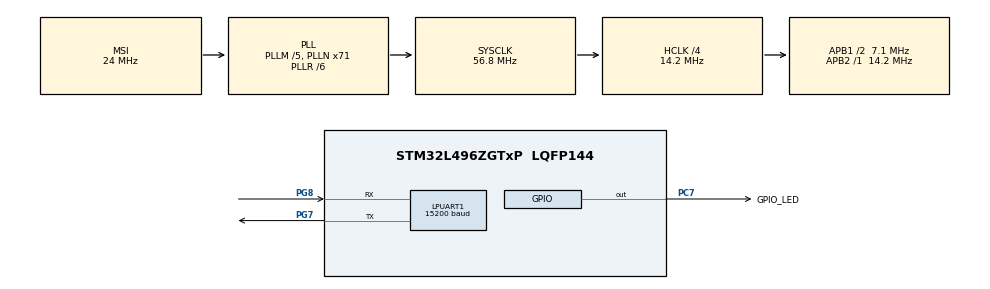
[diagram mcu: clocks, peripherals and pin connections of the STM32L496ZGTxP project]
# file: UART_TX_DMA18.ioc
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Dma.LPUART_TX.0.Direction=DMA_MEMORY_TO_PERIPH
Dma.LPUART_TX.0.Instance=DMA2_Channel6
Dma.LPUART_TX.0.MemDataAlignment=DMA_MDATAALIGN_BYTE
Dma.LPUART_TX.0.MemInc=DMA_MINC_ENABLE
Dma.LPUART_TX.0.Mode=DMA_CIRCULAR
Dma.LPUART_TX.0.PeriphDataAlignment=DMA_PDATAALIGN_BYTE
Dma.LPUART_TX.0.PeriphInc=DMA_PINC_DISABLE
Dma.LPUART_TX.0.Priority=DMA_PRIORITY_LOW
Dma.Request0=LPUART_TX
LPUART1.BaudRate=15200
LPUART1.WordLength=UART_WORDLENGTH_8B
Mcu.Family=STM32L4
Mcu.Name=STM32L496ZGTxP
Mcu.Package=LQFP144
NVIC.DMA2_Channel6_IRQn=true\:0\:0\:false\:false\:true\:false\:true\:true
NVIC.PriorityGroup=NVIC_PRIORITYGROUP_4
PA13\ (JTMS/SWDIO).Signal=SYS_JTMS-SWDIO
PC7.GPIO_Label=GPIO_LED
PC7.Signal=GPIO_Output
PG7.Mode=Asynchronous
PG7.Signal=LPUART1_TX
PG8.Mode=Asynchronous
PG8.Signal=LPUART1_RX
ProjectManager.HeapSize=0x200
ProjectManager.StackSize=0x400
ProjectManager.TargetToolchain=STM32CubeIDE
RCC.48MHZClocksFreq_Value=24000000
RCC.ADCFreq_Value=48000000
RCC.AHBCLKDivider=RCC_SYSCLK_DIV4
RCC.AHBFreq_Value=14200000
RCC.APB1CLKDivider=RCC_HCLK_DIV2
RCC.APB1Freq_Value=7100000
RCC.APB1TimFreq_Value=14200000
RCC.APB2Freq_Value=14200000
RCC.APB2TimFreq_Value=14200000
RCC.CortexFreq_Value=14200000
RCC.HCLKFreq_Value=14200000
RCC.HSE_VALUE=8000000
RCC.HSI48_VALUE=48000000
RCC.HSI_VALUE=16000000
RCC.LSE_VALUE=32768
RCC.MSIClockRange=RCC_MSIRANGE_9
RCC.MSI_VALUE=24000000
RCC.PLLM=5
RCC.PLLMUL=RCC_PLL_MUL9
RCC.PLLN=71
RCC.PLLR=RCC_PLLR_DIV6
RCC.PLLSAI1N=20
RCC.PRESCALERUSB=RCC_USBCLKSOURCE_PLL_DIV1_5
RCC.SYSCLKFreq_VALUE=56800000
RCC.SYSCLKSource=RCC_SYSCLKSOURCE_PLLCLK
RCC.SYSCLKSourceVirtual=RCC_SYSCLKSOURCE_PLLCLK
RCC.USBFreq_Value=48000000
RCC.VCOOutputFreq_Value=340800000
board=NUCLEO-L496ZG-P

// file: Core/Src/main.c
/* USER CODE BEGIN Header */
/**
  ******************************************************************************
  * @file           : main.c
  * @brief          : Main program body
  ******************************************************************************
  * @attention
  *
  * Copyright (c) 2023 STMicroelectronics.
  * All rights reserved.
  *
  * This software is licensed under terms that can be found in the LICENSE file
  * in the root directory of this software component.
  * If no LICENSE file comes with this software, it is provided AS-IS.
  *
  ******************************************************************************
  */
/* USER CODE END Header */
#include "main.h"

UART_HandleTypeDef hlpuart1;
DMA_HandleTypeDef hdma_lpuart_tx;

void SystemClock_Config(void);
static void MX_GPIO_Init(void);
static void MX_DMA_Init(void);
static void MX_LPUART1_UART_Init(void);

/* USER CODE BEGIN 0 */
uint8_t data[20];
uint8_t count =0;

void HAL_UART_TxHalfCpltCallback(UART_HandleTypeDef *huart)
{
  for (int i=0; i<10; i++)
    {
	data[i] = 1;
    }
}

void HAL_UART_TxCpltCallback(UART_HandleTypeDef *huart)
{
    for (int i=0; i<10; i++)
    {
	data[i] = 2;
    }
}

/* USER CODE END 0 */

int main(void)
{

  /* MCU Configuration--------------------------------------------------------*/

  /* Reset of all peripherals, Initializes the Flash interface and the Systick. */
  HAL_Init();

  /* Configure the system clock */
  SystemClock_Config();

  /* Initialize all configured peripherals */
  MX_GPIO_Init();
  MX_DMA_Init();
  MX_LPUART1_UART_Init();
  /* USER CODE BEGIN 2 */

  for (int i=0; i<20; i++)
     {
 	data[i] = 3;
     }

 HAL_UART_Transmit_DMA(&hlpuart1, data,sizeof(data));

  /* USER CODE END 2 */

  /* Infinite loop */
  while (1)
  {

    /* USER CODE BEGIN 3 */
	  HAL_GPIO_TogglePin(GPIO_LED_GPIO_Port, GPIO_LED_Pin);
	  HAL_Delay(500);
		count++;

		  if ((count%20) == 0)
		   {
		  //   HAL_UART_Transmit_DMA(&huart1, data, sizeof (data));
		 //  HAL_UART_Transmit_DMA(&hlpuart1, data, sizeof data);
		   }
		}

  /* USER CODE END 3 */
}

void SystemClock_Config(void)
{
  RCC_OscInitTypeDef RCC_OscInitStruct = {0};
  RCC_ClkInitTypeDef RCC_ClkInitStruct = {0};

  /** Configure the main internal regulator output voltage
  */
  if (HAL_PWREx_ControlVoltageScaling(PWR_REGULATOR_VOLTAGE_SCALE1) != HAL_OK)
  {
    Error_Handler();
  }

  /** Initializes the RCC Oscillators according to the specified parameters
  * in the RCC_OscInitTypeDef structure.
  */
  RCC_OscInitStruct.OscillatorType = RCC_OSCILLATORTYPE_MSI;
  RCC_OscInitStruct.MSIState = RCC_MSI_ON;
  RCC_OscInitStruct.MSICalibrationValue = 0;
  RCC_OscInitStruct.MSIClockRange = RCC_MSIRANGE_9;
  RCC_OscInitStruct.PLL.PLLState = RCC_PLL_ON;
  RCC_OscInitStruct.PLL.PLLSource = RCC_PLLSOURCE_MSI;
  RCC_OscInitStruct.PLL.PLLM = 5;
  RCC_OscInitStruct.PLL.PLLN = 71;
  RCC_OscInitStruct.PLL.PLLP = RCC_PLLP_DIV2;
  RCC_OscInitStruct.PLL.PLLQ = RCC_PLLQ_DIV2;
  RCC_OscInitStruct.PLL.PLLR = RCC_PLLR_DIV6;
  if (HAL_RCC_OscConfig(&RCC_OscInitStruct) != HAL_OK)
  {
    Error_Handler();
  }

  /** Initializes the CPU, AHB and APB buses clocks
  */
  RCC_ClkInitStruct.ClockType = RCC_CLOCKTYPE_HCLK|RCC_CLOCKTYPE_SYSCLK
                              |RCC_CLOCKTYPE_PCLK1|RCC_CLOCKTYPE_PCLK2;
  RCC_ClkInitStruct.SYSCLKSource = RCC_SYSCLKSOURCE_PLLCLK;
  RCC_ClkInitStruct.AHBCLKDivider = RCC_SYSCLK_DIV4;
  RCC_ClkInitStruct.APB1CLKDivider = RCC_HCLK_DIV2;
  RCC_ClkInitStruct.APB2CLKDivider = RCC_HCLK_DIV1;

  if (HAL_RCC_ClockConfig(&RCC_ClkInitStruct, FLASH_LATENCY_0) != HAL_OK)
  {
    Error_Handler();
  }
}

static void MX_LPUART1_UART_Init(void)
{

  hlpuart1.Instance = LPUART1;
  hlpuart1.Init.BaudRate = 15200;
  hlpuart1.Init.WordLength = UART_WORDLENGTH_8B;
  hlpuart1.Init.StopBits = UART_STOPBITS_1;
  hlpuart1.Init.Parity = UART_PARITY_NONE;
  hlpuart1.Init.Mode = UART_MODE_TX_RX;
  hlpuart1.Init.HwFlowCtl = UART_HWCONTROL_NONE;
  hlpuart1.Init.OneBitSampling = UART_ONE_BIT_SAMPLE_DISABLE;
  hlpuart1.AdvancedInit.AdvFeatureInit = UART_ADVFEATURE_NO_INIT;
  if (HAL_UART_Init(&hlpuart1) != HAL_OK)
  {
    Error_Handler();
  }

}

static void MX_DMA_Init(void)
{

  /* DMA controller clock enable */
  __HAL_RCC_DMA2_CLK_ENABLE();

  /* DMA interrupt init */
  /* DMA2_Channel6_IRQn interrupt configuration */
  HAL_NVIC_SetPriority(DMA2_Channel6_IRQn, 0, 0);
  HAL_NVIC_EnableIRQ(DMA2_Channel6_IRQn);

}

static void MX_GPIO_Init(void)
{
  GPIO_InitTypeDef GPIO_InitStruct = {0};

  /* GPIO Ports Clock Enable */
  __HAL_RCC_GPIOG_CLK_ENABLE();
  HAL_PWREx_EnableVddIO2();
  __HAL_RCC_GPIOC_CLK_ENABLE();
  __HAL_RCC_GPIOA_CLK_ENABLE();

  /*Configure GPIO pin Output Level */
  HAL_GPIO_WritePin(GPIO_LED_GPIO_Port, GPIO_LED_Pin, GPIO_PIN_RESET);

  /*Configure GPIO pin : GPIO_LED_Pin */
  GPIO_InitStruct.Pin = GPIO_LED_Pin;
  GPIO_InitStruct.Mode = GPIO_MODE_OUTPUT_PP;
  GPIO_InitStruct.Pull = GPIO_NOPULL;
  GPIO_InitStruct.Speed = GPIO_SPEED_FREQ_LOW;
  HAL_GPIO_Init(GPIO_LED_GPIO_Port, &GPIO_InitStruct);

}

void Error_Handler(void)
{
  __disable_irq();
  while (1)
  {
  }
}
